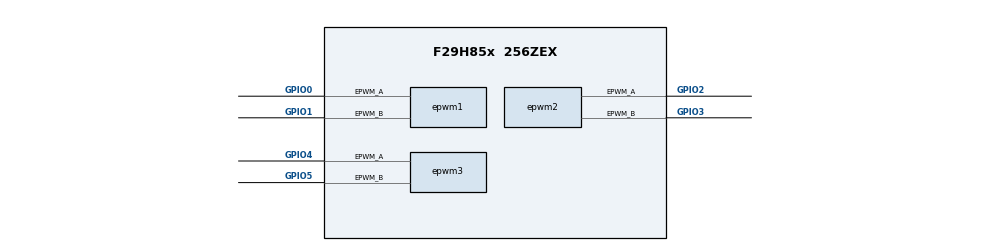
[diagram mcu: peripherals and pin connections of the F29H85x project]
/**
 * @cliArgs --device "F29H85x" --package "256ZEX" --part "F29H85x_256ZEX" --context "CPU1" --product "MCU_SDK_F29H85x@1.00.00.00"
 * @versions {"tool":"1.22.0+3877"}
 */

const divider15       = system.clockTree["PLL_REFDIV"];
divider15.divideValue = 1;

const multiplier1         = system.clockTree["PLL_IMULT"];
multiplier1.multiplyValue = 40;

const mux7       = system.clockTree["OSCCLKSRCSEL"];
mux7.inputSelect = "INTOSC2";

/**
 * Import the modules used in this configuration.
 */
const jtag  = scripting.addModule("/driverlib/jtag.js");
const epwm  = scripting.addModule("/driverlib/epwm.js", {}, false);
const epwm1 = epwm.addInstance();
const epwm2 = epwm.addInstance();
const epwm3 = epwm.addInstance();

/**
 * Write custom configuration values to the imported modules.
 */
epwm1.$name                  = "myEPWM1";
epwm1.epwm.$assign           = "EPWM1";
epwm1.epwm.epwm_aPin.$assign = "GPIO0";
epwm1.epwm.epwm_bPin.$assign = "GPIO1";

epwm2.$name                  = "myEPWM2";
epwm2.epwm.$assign           = "EPWM2";
epwm2.epwm.epwm_aPin.$assign = "GPIO2";
epwm2.epwm.epwm_bPin.$assign = "GPIO3";

epwm3.$name                  = "myEPWM3";
epwm3.epwm.$assign           = "EPWM3";
epwm3.epwm.epwm_aPin.$assign = "GPIO4";
epwm3.epwm.epwm_bPin.$assign = "GPIO5";
